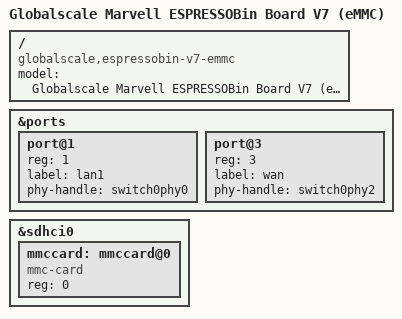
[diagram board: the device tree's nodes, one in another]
// SPDX-License-Identifier: (GPL-2.0+ OR MIT)
/*
 * Device Tree file for Globalscale Marvell ESPRESSOBin Board V7 with eMMC
 * Copyright (C) 2018 Marvell
 *
 * Romain Perier <romain.perier@free-electrons.com>
 * Konstantin Porotchkin <kostap@marvell.com>
 *
 */

#include "armada-3720-espressobin.dts"

/ {
	model = "Globalscale Marvell ESPRESSOBin Board V7 (eMMC)";
	compatible = "globalscale,espressobin-v7-emmc", "globalscale,espressobin-v7",
		     "globalscale,espressobin", "marvell,armada3720",
		     "marvell,armada3710";
};

&ports {
	port@1 {
		reg = <1>;
		label = "lan1";
		phy-handle = <&switch0phy0>;
	};

	port@3 {
		reg = <3>;
		label = "wan";
		phy-handle = <&switch0phy2>;
	};
};

&sdhci0 {
	status = "okay";

	#address-cells = <1>;
	#size-cells = <0>;
	mmccard: mmccard@0 {
		compatible = "mmc-card";
		reg = <0>;
	};
};
